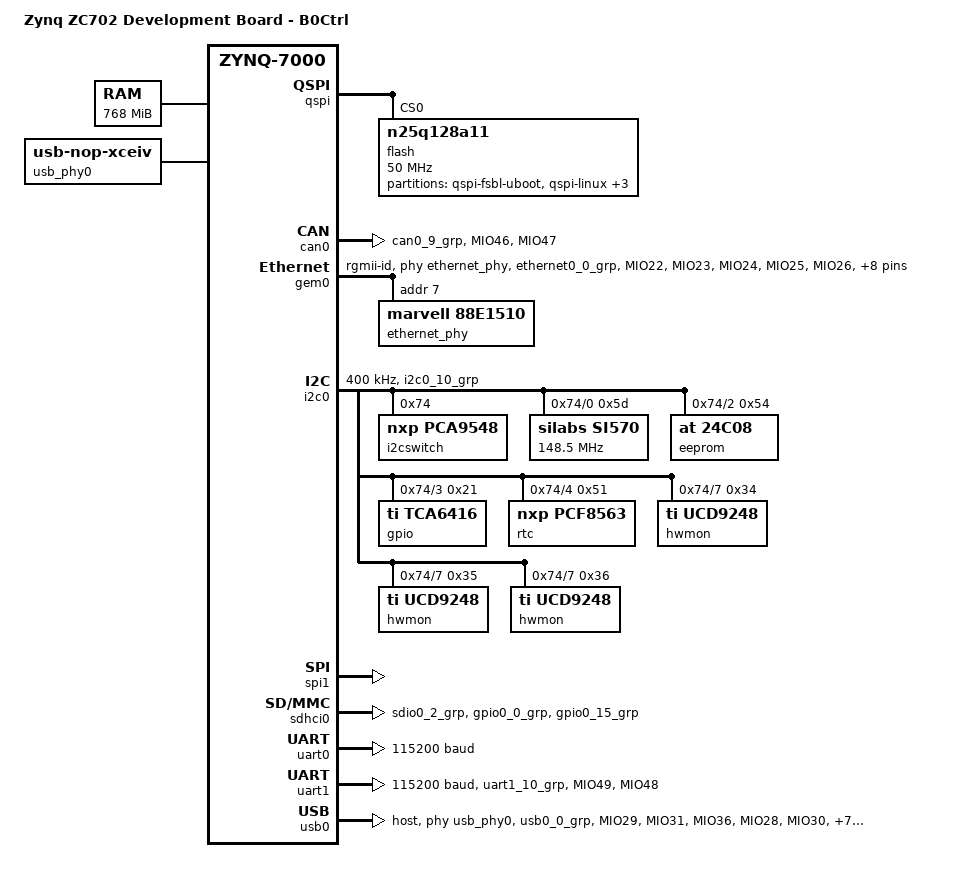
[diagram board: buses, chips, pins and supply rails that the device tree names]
/*
 * CAUTION: This file is automatically generated by Xilinx.
 * Version:  
 * Today is: Wed Jul 08 15:05:38 2015
*/


/dts-v1/;
/include/ "zynq-7000.dtsi"
/include/ "pl.dtsi"
/ {
	model = "Zynq ZC702 Development Board - B0Ctrl";
	compatible = "xlnx,zynq-zc702", "xlnx,zynq-7000";

	cpus {
		cpu@0 {
			operating-points = <666666 1000000 333333 1000000>;
		};
	};
	chosen {
		bootargs = "console=ttyPS0,115200 maxcpus=1 ip=192.168.1.10:::255.255.255.0:ZynqBoard:eth0:on root=/dev/ram rw earlyprintk";
		linux,stdout-path = &uart1;
		stdout-path = &uart1;
	};
	aliases {
		ethernet0 = &gem0;
		i2c0 = &i2c0;
		serial0 = &uart1;
		serial1 = &uart0;
		spi0 = &qspi;
	};
	memory {
		device_type = "memory";
		reg = <0x0 0x30000000>;
	};
	
	usb_phy0: phy0 {
		compatible = "usb-nop-xceiv";
		#phy-cells = <0>;
	};
};

&qspi {
	status = "okay";
	is-dual = <0>;
	num-cs = <1>;
	flash@0 {
		compatible = "n25q128a11";
		reg = <0x0>;
		spi-tx-bus-width = <1>;
		spi-rx-bus-width = <4>;
		spi-max-frequency = <50000000>;
		#address-cells = <1>;
		#size-cells = <1>;
		partition@qspi-fsbl-uboot {
			label = "qspi-fsbl-uboot";
			reg = <0x0 0x100000>;
		};
		partition@qspi-linux {
			label = "qspi-linux";
			reg = <0x100000 0x500000>;
		};
		partition@qspi-device-tree {
			label = "qspi-device-tree";
			reg = <0x600000 0x20000>;
		};
		partition@qspi-rootfs {
			label = "qspi-rootfs";
			reg = <0x620000 0x5E0000>;
		};
		partition@qspi-bitstream {
			label = "qspi-bitstream";
			reg = <0xC00000 0x400000>;
		};
	};
};

&can0 {
	status = "okay";
	pinctrl-names = "default";
	pinctrl-0 = <&pinctrl_can0_default>;
};

&clkc {
	ps-clk-frequency = <33333333>;
};

&gem0 {
	status = "okay";
	phy-mode = "rgmii-id";
	phy-handle = <&ethernet_phy>;
	pinctrl-names = "default";
	pinctrl-0 = <&pinctrl_gem0_default>;

	ethernet_phy: ethernet-phy@7 {
		reg = <7>;
		compatible = "marvell,88e1510";			// Paul
		device_type = "ethernet-phy";			// Paul
	};
};

&gpio0 {
	emio-gpio-width = <3>;				// Paul
	gpio-mask-high = <0x0>;				// Paul
	gpio-mask-low = <0x5600>;			// Paul
	xlnx,emio-gpio-width = <0x3>;			// Paul
	xlnx,mio-gpio-mask = <0x5600>;			// Paul
	pinctrl-names = "default";
	pinctrl-0 = <&pinctrl_gpio0_default>;
};

&i2c0 {
	clock-frequency = <400000>;
	i2c-reset = <&gpio0 13 0>;
	status = "okay";
	pinctrl-names = "default";
	pinctrl-0 = <&pinctrl_i2c0_default>;

	i2cswitch@74 {
		compatible = "nxp,pca9548";
		#address-cells = <1>;
		#size-cells = <0>;
		reg = <0x74>;

		i2c@0 {
			#address-cells = <1>;
			#size-cells = <0>;
			reg = <0>;
			si570: clock-generator@5d {
				#clock-cells = <0>;
				compatible = "silabs,si570";
				temperature-stability = <50>;
				reg = <0x5d>;
				factory-fout = <156250000>;
				clock-frequency = <148500000>;
			};
		};

		i2c@2 {
			#address-cells = <1>;
			#size-cells = <0>;
			reg = <2>;
			eeprom@54 {
				compatible = "at,24c08";
				reg = <0x54>;
			};
		};

		i2c@3 {
			#address-cells = <1>;
			#size-cells = <0>;
			reg = <3>;
			gpio@21 {
				compatible = "ti,tca6416";
				reg = <0x21>;
				gpio-controller;
				#gpio-cells = <2>;
			};
		};

		i2c@4 {
			#address-cells = <1>;
			#size-cells = <0>;
			reg = <4>;
			rtc@51 {
				compatible = "nxp,pcf8563";
				reg = <0x51>;
			};
		};

		i2c@7 {
			#address-cells = <1>;
			#size-cells = <0>;
			reg = <7>;
			hwmon@52 {
				compatible = "ti,ucd9248";
				reg = <52>;
			};
			hwmon@53 {
				compatible = "ti,ucd9248";
				reg = <53>;
			};
			hwmon@54 {
				compatible = "ti,ucd9248";
				reg = <54>;
			};
		};
	};
};

&pinctrl0 {
	pinctrl_can0_default: can0-default {
		mux {
			function = "can0";
			groups = "can0_9_grp";
		};

		conf {
			groups = "can0_9_grp";
			slew-rate = <0>;
			io-standard = <1>;
		};

		conf-rx {
			pins = "MIO46";
			bias-high-impedance;
		};

		conf-tx {
			pins = "MIO47";
			bias-disable;
		};
	};

	pinctrl_gem0_default: gem0-default {
		mux {
			function = "ethernet0";
			groups = "ethernet0_0_grp";
		};

		conf {
			groups = "ethernet0_0_grp";
			slew-rate = <0>;
			io-standard = <4>;
		};

		conf-rx {
			pins = "MIO22", "MIO23", "MIO24", "MIO25", "MIO26", "MIO27";
			bias-high-impedance;
			low-power-disable;
		};

		conf-tx {
			pins = "MIO16", "MIO17", "MIO18", "MIO19", "MIO20", "MIO21";
			bias-disable;
			low-power-enable;
		};

		mux-mdio {
			function = "mdio0";
			groups = "mdio0_0_grp";
		};

		conf-mdio {
			groups = "mdio0_0_grp";
			slew-rate = <0>;
			io-standard = <1>;
			bias-disable;
		};
	};

	pinctrl_gpio0_default: gpio0-default {
		mux {
			function = "gpio0";
			groups = "gpio0_7_grp", "gpio0_8_grp", "gpio0_9_grp",
				 "gpio0_10_grp", "gpio0_11_grp", "gpio0_12_grp",
				 "gpio0_13_grp", "gpio0_14_grp";
		};

		conf {
			groups = "gpio0_7_grp", "gpio0_8_grp", "gpio0_9_grp",
				 "gpio0_10_grp", "gpio0_11_grp", "gpio0_12_grp",
				 "gpio0_13_grp", "gpio0_14_grp";
			slew-rate = <0>;
			io-standard = <1>;
		};

		conf-pull-up {
			pins = "MIO9", "MIO10", "MIO11", "MIO12", "MIO13", "MIO14";
			bias-pull-up;
		};

		conf-pull-none {
			pins = "MIO7", "MIO8";
			bias-disable;
		};
	};

	pinctrl_i2c0_default: i2c0-default {
		mux {
			groups = "i2c0_10_grp";
			function = "i2c0";
		};

		conf {
			groups = "i2c0_10_grp";
			bias-pull-up;
			slew-rate = <0>;
			io-standard = <1>;
		};
	};

	pinctrl_sdhci0_default: sdhci0-default {
		mux {
			groups = "sdio0_2_grp";
			function = "sdio0";
		};

		conf {
			groups = "sdio0_2_grp";
			slew-rate = <0>;
			io-standard = <1>;
			bias-disable;
		};

		mux-cd {
			groups = "gpio0_0_grp";
			function = "sdio0_cd";
		};

		conf-cd {
			groups = "gpio0_0_grp";
			bias-high-impedance;
			bias-pull-up;
			slew-rate = <0>;
			io-standard = <1>;
		};

		mux-wp {
			groups = "gpio0_15_grp";
			function = "sdio0_wp";
		};

		conf-wp {
			groups = "gpio0_15_grp";
			bias-high-impedance;
			bias-pull-up;
			slew-rate = <0>;
			io-standard = <1>;
		};
	};

	pinctrl_uart1_default: uart1-default {
		mux {
			groups = "uart1_10_grp";
			function = "uart1";
		};
		conf {
			groups = "uart1_10_grp";
			slew-rate = <0>;
			io-standard = <1>;
		};
		conf-rx {
			pins = "MIO49";
			bias-high-impedance;
		};
		conf-tx {
			pins = "MIO48";
			bias-disable;
		};
	};

	pinctrl_usb0_default: usb0-default {
		mux {
			groups = "usb0_0_grp";
			function = "usb0";
		};
		conf {
			groups = "usb0_0_grp";
			slew-rate = <0>;
			io-standard = <1>;
		};
		conf-rx {
			pins = "MIO29", "MIO31", "MIO36";
			bias-high-impedance;
		};
		conf-tx {
			pins = "MIO28", "MIO30", "MIO32", "MIO33", "MIO34",
			       "MIO35", "MIO37", "MIO38", "MIO39";
			bias-disable;
		};
	};
};

&intc {
	num_cpus = <2>;
	num_interrupts = <96>;
};

&spi1 {
	is-decoded-cs = <0>;
	num-cs = <3>;
	status = "okay";
	xlnx,has-ss0 = <0x1>;				// Paul
	xlnx,has-ss1 = <0x1>;				// Paul
	xlnx,has-ss2 = <0x1>;				// Paul
};

&sdhci0 {
	status = "okay";
	pinctrl-names = "default";
	pinctrl-0 = <&pinctrl_sdhci0_default>;
};

&ttc0 {									// Paul
	interrupt-names = "ttc0", "ttc1", "ttc2";
	xlnx,ttc-clk0-clksrc = <0x0>;
	xlnx,ttc-clk0-freq-hz = <0x69f6bcb>;
	xlnx,ttc-clk1-clksrc = <0x0>;
	xlnx,ttc-clk1-freq-hz = <0x69f6bcb>;
	xlnx,ttc-clk2-clksrc = <0x0>;
	xlnx,ttc-clk2-freq-hz = <0x69f6bcb>;
};

&uart0 {
	current-speed = <115200>;
	device_type = "serial";
	port-number = <1>;
	status = "okay";
};

&uart1 {
	status = "okay";
	current-speed = <115200>;
	device_type = "serial";
	port-number = <0>;
	pinctrl-names = "default";
	pinctrl-0 = <&pinctrl_uart1_default>;
};

&usb0 {
	status = "okay";
	dr_mode = "host";
	usb-phy = <&usb_phy0>;
	pinctrl-names = "default";
	pinctrl-0 = <&pinctrl_usb0_default>;
};
